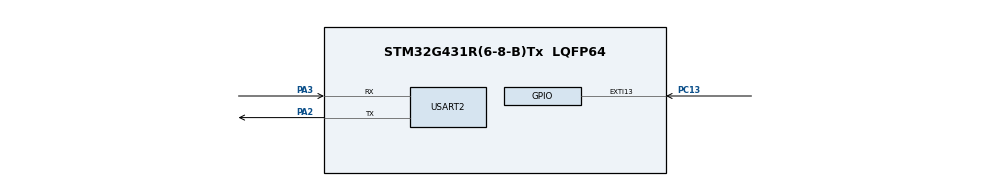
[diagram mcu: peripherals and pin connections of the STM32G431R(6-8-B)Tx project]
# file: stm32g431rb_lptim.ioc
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Mcu.Family=STM32G4
Mcu.Name=STM32G431R(6-8-B)Tx
Mcu.Package=LQFP64
NVIC.EXTI15_10_IRQn=true\:0\:0\:false\:false\:true\:true\:true\:true
NVIC.PriorityGroup=NVIC_PRIORITYGROUP_4
PA2.Mode=Asynchronous
PA2.Signal=USART2_TX
PA3.Mode=Asynchronous
PA3.Signal=USART2_RX
PC13.GPIO_ModeDefaultEXTI=GPIO_MODE_IT_FALLING
PC13.Signal=GPXTI13
PC14-OSC32_IN.Mode=LSE-External-Oscillator
PC14-OSC32_IN.Signal=RCC_OSC32_IN
PC15-OSC32_OUT.Mode=LSE-External-Oscillator
PC15-OSC32_OUT.Signal=RCC_OSC32_OUT
ProjectManager.HeapSize=0x200
ProjectManager.StackSize=0x400
ProjectManager.TargetToolchain=STM32CubeIDE
RCC.AHBFreq_Value=16000000
RCC.APB1Freq_Value=16000000
RCC.APB1TimFreq_Value=16000000
RCC.APB2Freq_Value=16000000
RCC.APB2TimFreq_Value=16000000
RCC.CortexFreq_Value=16000000
RCC.EXTERNAL_CLOCK_VALUE=12288000
RCC.HCLKFreq_Value=16000000
RCC.HSE_VALUE=8000000
RCC.HSI48_VALUE=48000000
RCC.HSI_VALUE=16000000
RCC.LPTIM1CLockSelection=RCC_LPTIM1CLKSOURCE_LSE
RCC.SYSCLKFreq_VALUE=16000000
RCC.USBFreq_Value=64000000
RCC.VCOOutputFreq_Value=128000000
USART2.VirtualMode-Asynchronous=VM_ASYNC
VP_LPTIM1_VS_LPTIM_counterModeInternalClock.Mode=Counts__internal_clock_event_00
VP_SYS_VS_DBSignals.Mode=DisableDeadBatterySignals
board=custom

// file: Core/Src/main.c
/* USER CODE BEGIN Header */
/**
  ******************************************************************************
  * @file           : main.c
  * @brief          : Main program body
  ******************************************************************************
  * @attention
  *
  * Copyright (c) 2024 STMicroelectronics.
  * All rights reserved.
  *
  * This software is licensed under terms that can be found in the LICENSE file
  * in the root directory of this software component.
  * If no LICENSE file comes with this software, it is provided AS-IS.
  *
  ******************************************************************************
  */
/* USER CODE END Header */
#include "main.h"

/* USER CODE BEGIN Includes */
#include <stdio.h>
/* USER CODE END Includes */

UART_HandleTypeDef huart2;

void SystemClock_Config(void);
static void MX_GPIO_Init(void);
static void MX_LPTIM1_Init(void);
static void MX_USART2_UART_Init(void);
/* USER CODE BEGIN PFP */
int _write(int file, char *ptr, int len)
{
  HAL_UART_Transmit(&huart2, (uint8_t *)ptr, len, HAL_MAX_DELAY);
  return len;
}
/* USER CODE END PFP */

/* USER CODE BEGIN 0 */
void HAL_GPIO_EXTI_Callback(uint16_t GPIO_Pin)
{
  if(GPIO_Pin == GPIO_PIN_13)
  {
    static int seq=0;

    switch(seq)
    {
      case 0:
        printf("Start value: %d\r\n", (int)LL_LPTIM_GetCounter(LPTIM1));
        LL_LPTIM_Enable(LPTIM1);
        LL_LPTIM_SetAutoReload(LPTIM1, 0xFFFF);
        LL_LPTIM_StartCounter(LPTIM1, LL_LPTIM_OPERATING_MODE_CONTINUOUS);
        seq++;
        break;

      case 1:
        printf("Reset value: %d\r\n", (int)LL_LPTIM_GetCounter(LPTIM1));
        LL_LPTIM_SetAutoReload(LPTIM1, 0xFFFF);
        LL_LPTIM_StartCounter(LPTIM1, LL_LPTIM_OPERATING_MODE_CONTINUOUS);
        seq++;
        break;

      case 2:
        printf("Counter value: %d\r\n", (int)LL_LPTIM_GetCounter(LPTIM1));

        seq++;
        break;

      case 3: //to initiate LPTIM counter
        printf("Counter value: %d\r\n", (int)LL_LPTIM_GetCounter(LPTIM1));
        LL_LPTIM_SetAutoReload(LPTIM1, 0x1);
        LL_LPTIM_StartCounter(LPTIM1, LL_LPTIM_OPERATING_MODE_ONESHOT);
        //LL_LPTIM_Disable(LPTIM1);
        seq=1;
        break;
    }
  }
}
/* USER CODE END 0 */

int main(void)
{

  /* MCU Configuration--------------------------------------------------------*/

  /* Reset of all peripherals, Initializes the Flash interface and the Systick. */
  HAL_Init();

  /* Configure the system clock */
  SystemClock_Config();

  /* Initialize all configured peripherals */
  MX_GPIO_Init();
  MX_LPTIM1_Init();
  MX_USART2_UART_Init();

  /* Infinite loop */
  while (1)
  {

  }
}

void SystemClock_Config(void)
{
  LL_FLASH_SetLatency(LL_FLASH_LATENCY_0);
  while(LL_FLASH_GetLatency() != LL_FLASH_LATENCY_0)
  {
  }
  LL_PWR_SetRegulVoltageScaling(LL_PWR_REGU_VOLTAGE_SCALE1);
  LL_RCC_HSI_Enable();
   /* Wait till HSI is ready */
  while(LL_RCC_HSI_IsReady() != 1)
  {
  }

  LL_RCC_HSI_SetCalibTrimming(64);
  LL_PWR_EnableBkUpAccess();
  LL_RCC_LSE_SetDriveCapability(LL_RCC_LSEDRIVE_LOW);
  LL_RCC_LSE_Enable();
   /* Wait till LSE is ready */
  while(LL_RCC_LSE_IsReady() != 1)
  {
  }

  LL_RCC_SetSysClkSource(LL_RCC_SYS_CLKSOURCE_HSI);
   /* Wait till System clock is ready */
  while(LL_RCC_GetSysClkSource() != LL_RCC_SYS_CLKSOURCE_STATUS_HSI)
  {
  }

  /* Set AHB prescaler*/
  LL_RCC_SetAHBPrescaler(LL_RCC_SYSCLK_DIV_1);
  LL_RCC_SetAPB1Prescaler(LL_RCC_APB1_DIV_1);
  LL_RCC_SetAPB2Prescaler(LL_RCC_APB2_DIV_1);
  LL_SetSystemCoreClock(16000000);

   /* Update the time base */
  if (HAL_InitTick (TICK_INT_PRIORITY) != HAL_OK)
  {
    Error_Handler();
  }
}

static void MX_LPTIM1_Init(void)
{

  LL_RCC_SetLPTIMClockSource(LL_RCC_LPTIM1_CLKSOURCE_LSE);

  /* Peripheral clock enable */
  LL_APB1_GRP1_EnableClock(LL_APB1_GRP1_PERIPH_LPTIM1);

  LL_LPTIM_SetClockSource(LPTIM1, LL_LPTIM_CLK_SOURCE_INTERNAL);
  LL_LPTIM_SetPrescaler(LPTIM1, LL_LPTIM_PRESCALER_DIV1);
  LL_LPTIM_SetPolarity(LPTIM1, LL_LPTIM_OUTPUT_POLARITY_REGULAR);
  LL_LPTIM_SetUpdateMode(LPTIM1, LL_LPTIM_UPDATE_MODE_IMMEDIATE);
  LL_LPTIM_SetCounterMode(LPTIM1, LL_LPTIM_COUNTER_MODE_INTERNAL);
  LL_LPTIM_TrigSw(LPTIM1);
  LL_LPTIM_SetInput1Src(LPTIM1, LL_LPTIM_INPUT1_SRC_GPIO);
  LL_LPTIM_SetInput2Src(LPTIM1, LL_LPTIM_INPUT2_SRC_GPIO);

}

static void MX_USART2_UART_Init(void)
{

  huart2.Instance = USART2;
  huart2.Init.BaudRate = 115200;
  huart2.Init.WordLength = UART_WORDLENGTH_8B;
  huart2.Init.StopBits = UART_STOPBITS_1;
  huart2.Init.Parity = UART_PARITY_NONE;
  huart2.Init.Mode = UART_MODE_TX_RX;
  huart2.Init.HwFlowCtl = UART_HWCONTROL_NONE;
  huart2.Init.OverSampling = UART_OVERSAMPLING_16;
  huart2.Init.OneBitSampling = UART_ONE_BIT_SAMPLE_DISABLE;
  huart2.Init.ClockPrescaler = UART_PRESCALER_DIV1;
  huart2.AdvancedInit.AdvFeatureInit = UART_ADVFEATURE_NO_INIT;
  if (HAL_UART_Init(&huart2) != HAL_OK)
  {
    Error_Handler();
  }
  if (HAL_UARTEx_SetTxFifoThreshold(&huart2, UART_TXFIFO_THRESHOLD_1_8) != HAL_OK)
  {
    Error_Handler();
  }
  if (HAL_UARTEx_SetRxFifoThreshold(&huart2, UART_RXFIFO_THRESHOLD_1_8) != HAL_OK)
  {
    Error_Handler();
  }
  if (HAL_UARTEx_DisableFifoMode(&huart2) != HAL_OK)
  {
    Error_Handler();
  }

}

static void MX_GPIO_Init(void)
{
  GPIO_InitTypeDef GPIO_InitStruct = {0};

  /* GPIO Ports Clock Enable */
  __HAL_RCC_GPIOC_CLK_ENABLE();
  __HAL_RCC_GPIOA_CLK_ENABLE();

  /*Configure GPIO pin : PC13 */
  GPIO_InitStruct.Pin = GPIO_PIN_13;
  GPIO_InitStruct.Mode = GPIO_MODE_IT_FALLING;
  GPIO_InitStruct.Pull = GPIO_NOPULL;
  HAL_GPIO_Init(GPIOC, &GPIO_InitStruct);

  /* EXTI interrupt init*/
  HAL_NVIC_SetPriority(EXTI15_10_IRQn, 0, 0);
  HAL_NVIC_EnableIRQ(EXTI15_10_IRQn);

}

void Error_Handler(void)
{
  __disable_irq();
  while (1)
  {
  }
}
